# SAM9X75D1GN2 register map
Vendor: Microchip Technology; Series: SAM9X7; File version: 0
Registers are 32-bit, read-write, reset 0x0 unless marked. A register's access mark holds for its fields unless they carry their own. Offsets are from the block's base; [hi:lo] are bit positions; lines under a group give offsets from that group; {n}, {i} and the like mark numbered series; 'fields as' and 'values as' point back to an identical list.

## GMAC (part 2 of 2) — Gigabit Ethernet MAC
Base 0xF802C000
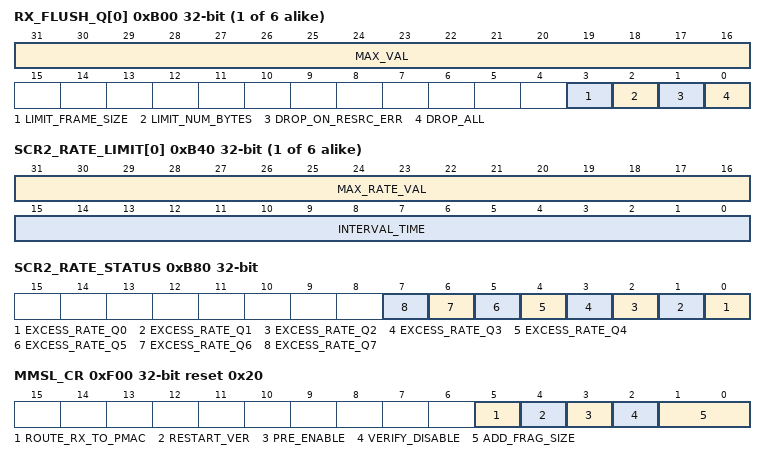
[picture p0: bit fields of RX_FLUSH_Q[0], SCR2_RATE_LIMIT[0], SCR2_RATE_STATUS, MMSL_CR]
{0xB00+4i} RX_FLUSH_Q[{i}] (i=0..5) — Receive Queue Flush Register (index = 0)
  [31:16] MAX_VAL — Maximum Value for the Received Frame Size or Number of 128-Byte Chunk
  [3] LIMIT_FRAME_SIZE — Maximum Frame-length Received
    0=DISABLED (No effect.); 1=ENABLED (When set, MAX_VAL indicates the maximum frame-length in bytes that may be received. Frames exceeding this length will be dropped. This traffic policing function is relevant to the 802.1Qci standard which specifies stream filtering based on a maximum service data unit (SDU) size.)
  [2] LIMIT_NUM_BYTES — Limitation of the Number of 128-Byte Chunk of Data Stored in the Memory of this Queue
    0=DISABLED (No effect.); 1=ENABLED (Limits the number of 128 byte chunks of data received for this queue and already stored in the memory of the queue awaiting DMA memory writes to the value defined in the field MAX_VAL.)
  [1] DROP_ON_RESRC_ERR — Drop on Resource Error
    0=DISABLED (No effect.); 1=ENABLED (If a free DMA descriptor for this queue cannot be obtained (also referred to as lack of descriptor resource and occurs when the software either cannot free up descriptors quickly enough to meet the receive traffic rate or has deliberately decided not to free any descriptors), all new frames received on this queue will be automatically discarded.)
  [0] DROP_ALL — Drop All Frames
    0=DISABLED (No effect.); 1=ENABLED (Drops all frames of this queue.)
{0xB40+4i} SCR2_RATE_LIMIT[{i}] (i=0..5) — Screening 2 Rate Limit Register (index = 0)
  [31:16] MAX_RATE_VAL — Maximum Rate Value for the Interval Time
  [15:0] INTERVAL_TIME — Interval Time for Maximum Rate Checking
0xB80 SCR2_RATE_STATUS ro — Screening 2 Rate Status Register
  [all] fields
    0=No excessive rate in screener since the last read of GMAC_SCR2_RATE_STATUS; 1=A screener rate limiting mechanism has been triggered since the last read of GMAC_SCR2_RATE_STATUS
  [n] EXCESS_RATE_Q{n} (n=0..7) — Excessive Screener Rate Queue {n}
0xF00 MMSL_CR reset 0x20 — MMSL Control Register
  [5] ROUTE_RX_TO_PMAC — Route Received Frames to Preemptive MAC
    0=Routes all received to express MAC (eMAC); 1=Routes all received frames to preemptive MAC (pMAC)
  [4] RESTART_VER — Restart the Verification Procedure (Write-only)
    0=No effect; 1=Restarts the verification procedure. Writing a one to this bit has no effect if any of the following are true: PRE_ENABLE=0, VERIFY_DISABLE=1 or the verification procedure is already in progress. When preemption is active, ROUTE_RX_TO_PMAC must be set to zero before writing to the RESTART_VER bit. This bit always returns zero when read.
  [3] PRE_ENABLE — Preemption Operation Enable
    0=Disables the preemption operation and verify mpackets will not be responded to or sent. If a preemption is in progress, the current preemption will complete and no more preemption will occur.; 1=Enables the preemption by starting the verification procedure when VERIFY_DISABLE=0. Preemption can occur only once the verification process completes. If VERIFY_DISABLE=1, preemption can occur immediately.
  [2] VERIFY_DISABLE — 802.3br Support Check for the Link Partner
    0=Enables the 802.3br support check for the link partner; 1=Disables the 802.3br support check for the link partner and preemption is enabled as soon as PRE_ENABLE=1
  [1:0] ADD_FRAG_SIZE — PMAC Minimum Number of Bytes before Preemption
    0=64_BYTES (A minimum of 64 bytes can be sent by pMAC before any preemption. The value can be changed only when PRE_ENABLE is cleared); 1=128_BYTES (A minimum of 128 bytes can be sent by pMAC before any preemption. The value can be changed only when PRE_ENABLE is cleared); 2=192_BYTES (A minimum of 192 bytes can be sent by pMAC before any preemption. The value can be changed only when PRE_ENABLE is cleared); 3=256_BYTES (A minimum of 256 bytes can be sent by pMAC before any preemption. The value can be changed only when PRE_ENABLE is cleared)
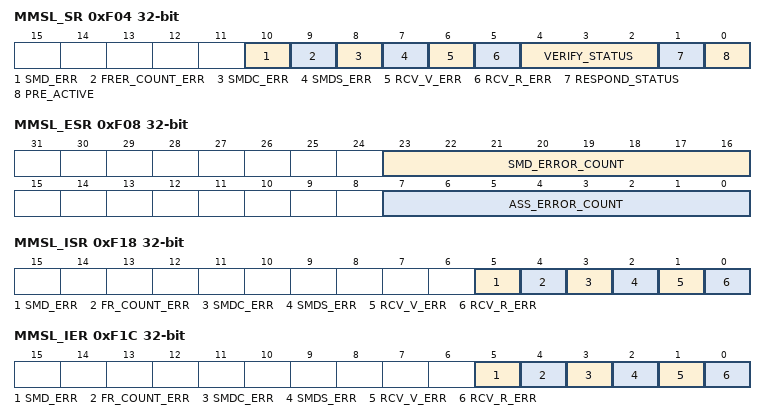
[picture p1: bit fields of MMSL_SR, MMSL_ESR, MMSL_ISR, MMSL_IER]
0xF04 MMSL_SR ro — MMSL Status Register
  [10] SMD_ERR — Illegal Start Mpacket Delimiter Received (Clear on read)
    0=No error since the last read of GMAC_MMSL_SR; 1=An illegal SMD (different from Express, Verify, Response, Start Preemptible or Continuation Preemptible SMD) has been received since the last read of GMAC_MMSL_SR
  [9] FRER_COUNT_ERR — Frame Counter Error (Clear on read)
    0=No error since the last read of GMAC_MMSL_SR; 1=A frame counter error occurred since the last read of GMAC_MMSL_SR. A frame counter error occurs when the SMD-C received indicates a different frame count than expected (i.e. the fragment belongs to another frame and not to the Start packet already received before this) or when a fragment error happened, which means the field following the SMD-C received was encoding a different fragment count than it was supposed to be.
  [8] SMDC_ERR — SMD-C Received When Waiting an SMD-S (Clear on read)
    0=No error since the last read of GMAC_MMSL_SR; 1=An SMD-C has been received when an SMD-S was expected, since the last read of GMAC_MMSL_SR
  [7] SMDS_ERR — SMD-S Received When Waiting an SMD-C (Clear on read)
    0=No error since the last read of GMAC_MMSL_SR; 1=An SMD-S has been received when an SMD-C was expected, since the last read of GMAC_MMSL_SR
  [6] RCV_V_ERR — Incorrect Verification Mpacket Received (Clear on read)
    0=No error since the last read of GMAC_MMSL_SR; 1=An incorrect verification mPacket has been received since the last read of GMAC_MMSL_SR
  [5] RCV_R_ERR — Incorrect Response Mpacket Received (Clear on read)
    0=No error since the last read of GMAC_MMSL_SR; 1=An incorrect response mPacket has been received since the last read of GMAC_MMSL_SR
  [4:2] VERIFY_STATUS — Verification Status
    0=INIT_VERIFICATION (Initialization); 1=VERIFICATION_IDLE (Idle); 2=SEND_VERIFY (Sending a verify command); 3=WAIT_FOR_RESPONSE (Waiting for a response); 4=VERIFIED; 5=VERIFY_FAIL (Failure during the verify operation)
  [1] RESPOND_STATUS — Response Status
    0=R_IDLE (Idle); 1=SEND_RESPOND (Sending)
  [0] PRE_ACTIVE — Preemption Status
    0=Preemption is inactive; 1=Preemption is active when the verification process is completed or when GMAC_MMSL_CR.VERIFY_DISABLE=1 and GMAC_MMSL_CR.PRE_ACTIVE=1
0xF08 MMSL_ESR ro — MMSL Error Statistics Register
  [23:16] SMD_ERROR_COUNT — Number of Rejected Frames or Fragments due to unknown SMD (Clear on read)
  [7:0] ASS_ERROR_COUNT — Number of Frames with Reassembly Errors (Clear on read)
0xF0C MMSL_ASS_OK ro — MMSL Frame Re-Assembled OK Register
  [16:0] ASS_OK_COUNT — Number of Correctly Re-Assembled Frames (Clear on read)
0xF10 MMSL_RXFRAG_CNT ro — MMSL Received Fragment Counter Register
  [16:0] FRAG_COUNT_RX — Number of Received Fragments (Clear on read)
0xF14 MMSL_TXFRAG_CNT ro — MMSL Transmitted Fragment Counter Register
  [16:0] FRAG_COUNT_TX — Number of Transmitted Fragments (Clear on read)
0xF18 MMSL_ISR — MMSL Interrupt Status Register
  [5] SMD_ERR — Illegal SMD Received (Clear on read)
    0=No illegal SMD received since the last read of GMAC_MMSL_ISR; 1=Illegal SMD received (different from Express, Verify, Response, Start Preemptible or Continuation Preemptible) since the last read of GMAC_MMSL_ISR
  [4] FR_COUNT_ERR — Illegal SMD Received (Clear on read)
    0=No frame count error detected since the last read of GMAC_MMSL_ISR; 1=The SMD-C received since the last read of GMAC_MMSL_ISR, indicates a different frame count than expected (i.e. the fragment belongs to another frame and not to the Start packet already received before this) or if a Fragment error happened, which means the field following the SMD-C received was encoding a different fragment count than it was supposed to be.
  [3] SMDC_ERR — SMD-C Received When Waiting an SMD-S (Clear on read)
    values as MMSL_SR.SMDC_ERR
  [2] SMDS_ERR — SMD-S Received When Waiting an SMD-C (Clear on read)
    values as MMSL_SR.SMDS_ERR
  [1] RCV_V_ERR — Incorrect Verification Mpacket Received (Clear on read)
    values as MMSL_SR.RCV_V_ERR
  [0] RCV_R_ERR — Incorrect Response Mpacket Received (Clear on read)
    values as MMSL_SR.RCV_R_ERR
0xF1C MMSL_IER — MMSL Interrupt Enable Register
  [5] SMD_ERR — Illegal SMD Received
  [4] FR_COUNT_ERR — Illegal SMD Received
  [3] SMDC_ERR — SMD-C Received When Waiting an SMD-S
  [2] SMDS_ERR — SMD-S Received When Waiting an SMD-C
  [1] RCV_V_ERR — Incorrect Verification Mpacket Received
  [0] RCV_R_ERR — Incorrect Response Mpacket Received
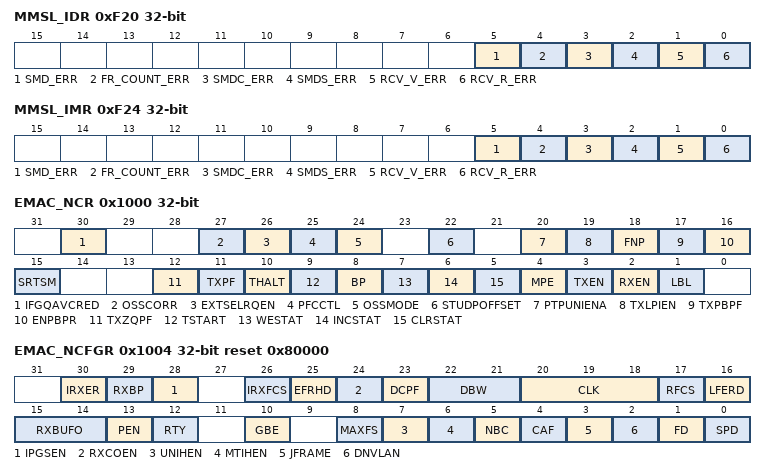
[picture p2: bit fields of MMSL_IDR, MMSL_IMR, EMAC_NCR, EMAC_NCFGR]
0xF20 MMSL_IDR — MMSL Interrupt Disable Register
  fields as MMSL_IER
0xF24 MMSL_IMR ro — MMSL Interrupt Mask Register
  fields as MMSL_IER
0x1000 EMAC_NCR — Express MAC Network Control Register
  [30] IFGQAVCRED — Credit-Based Shaping Algorithm Modification
    0=No modification of the CBS algorithm; 1=Modifies the CBS algorithm so the IFG/IPG associated with a transmit frame counts towards its 802.1Qav credit
  [27] OSSCORR — 1588 One Step Sync Mode Correction Field
    0=Disables updating the correction field of PTP 1588 version 2 sync frames by adding current TSU timer value; 1=Enables updating the correction field of PTP 1588 version 2 sync frames by adding current TSU timer value
  [26] EXTSELRQEN — External Selection of Receive Queue Enable
    0=Disables external selection of receive queue; 1=Enables external selection of receive queue
  [25] PFCCTL — Multiple PFC Pause quantum Enable
    0=Disables multiple PFC pause quantums; 1=Enables multiple PFC pause quantums, one per pause priority
  [24] OSSMODE — One Step Sync Mode
    0=1588 One Step Sync Mode is disabled; 1=1588 One Step Sync Mode is enabled. Replaces timestamp field in the 1588 header for TX Sync Frames with the current TSU timer value.
  [22] STUDPOFFSET — Store UDP Offset
    0=Normal operations; 1=The upper 16 bits of the CRC of every received frame are replaced with the offset from start of frame to the beginning of the UDP or TCP header. The lower 16 bits of the CRC are replaced with zero and reserved for future use. The offset is measured in units of 2 bytes.
  [20] PTPUNIENA — Detection of Unicast PTP Frames Enable
    0=Disables detection of unicast PTP frames; 1=Enables detection of unicast PTP frames
  [19] TXLPIEN — Enable LPI Transmission
  [18] FNP — Flush Next Packet (Write-only)
    0=No effect; 1=Flushes the next packet from the receive memory. This will only have an effect if the DMA is not currently writing a packet already stored in the receive memory to system memory.
  [17] TXPBPF — Transmit PFC Priority-based Pause Frame (Write-only)
    0=No effect; 1=Takes the values stored in the Transmit PFC Pause Register
  [16] ENPBPR — Enable PFC Priority-based Pause Reception
    0=Disables PFC Priority Based Pause Reception capabilities; 1=Enables PFC Priority Based Pause Reception capabilities by enabling the PFC negotiation and recognition of priority-based pause frames
  [15] SRTSM — Store Receive Timestamp to Memory
    0=Normal operation; 1=Causes the CRC of every received frame to be replaced with the value of the nanoseconds field of the 1588 timer that was captured as the receive frame passed the message timestamp point. Note that bit RFCS in register GMAC_NCFGR may not be set to 1 when the timer should be captured.
  [12] TXZQPF — Transmit Zero Quantum Pause Frame (Write-only)
    0=No effect; 1=Generates a pause frame with zero quantum to be transmitted
  [11] TXPF — Transmit Pause Frame (Write-only)
    0=No effect; 1=Generates a pause frame to be transmitted
  [10] THALT — Transmit Halt (Write-only)
    0=No effect; 1=Halts transmission as soon as any ongoing frame transmission ends
  [9] TSTART — Start Transmission (Write-only)
    0=No effect; 1=Starts transmission
  [8] BP — Back Pressure
    0=No effect; 1=When the MAC is set in 10M or 100M Half Duplex mode, forces collisions on all received frames. Ignored in Gigabit Half Duplex mode.
  [7] WESTAT — Write Enable for Statistics Registers
    0=Forces the statistics registers to be in read-only mode for normal operation mode; 1=Makes the statistics registers writable for functional test purposes
  [6] INCSTAT — Increment Statistics Registers (Write-only)
  [5] CLRSTAT — Clear Statistics Registers (Write-only)
    0=No effect; 1=Clears the statistics registers
  [4] MPE — Management Port Enable
    0=Forces GMDIO to high impedance state and MDC low; 1=Enables the management port
  [3] TXEN — Transmit Enable
    0=Stops transmission immediately, the transmit pipeline and control registers will be cleared and the Transmit Queue Pointer Register will reset to point to the start of the transmit descriptor list; 1=Enables the GMAC transmitter to send data
  [2] RXEN — Receive Enable
    0=Stops frame reception immediately and the receive pipeline will be cleared. The Receive Queue Pointer Register is unaffected.; 1=Enables the GMAC to receive data
  [1] LBL — Loop Back Local
    0=Normal operating mode (no loop back); 1=Connects GTX to GRX, GTXEN to GRXDV and forces Full Duplex mode. GRXCK and GTXCK may malfunction as the GMAC is switched into and out of internal loop back. It is important that receive and transmit circuits have already been disabled when making the switch into and out of internal loop back.
0x1004 EMAC_NCFGR reset 0x80000 — Express MAC Network Configuration Register
  [30] IRXER — Ignore Receive Error from PHY
    0=IRXER_0; 1=GRXER has no effect on the GMAC's operation when GRXDV is low. Set this bit when using the RGMII wrapper in Half Duplex mode.
  [29] RXBP — Receive Bad Preamble
    0=Rejects frames with non-standard preamble; 1=Accepts frames with non-standard preamble
  [28] IPGSEN — Inter Packet Gap Stretch Enable
    0=The transmit IPG cannot be increased; 1=The transmit IPG can be increased above 96 bit times depending on the previous frame length using the IPG Stretch Register
  [26] IRXFCS — Ignore RX FCS
    0=Normal operation, frames with FCS/CRC errors are rejected; 1=Frames with FCS/CRC errors are rejected. FCS error statistics are still collected for frames with bad FCS and FCS status is recorded in frame's DMA descriptor.
  [25] EFRHD — Enable Frames Received in Half Duplex
    0=Disables frames to be received in Half Duplex mode while transmitting; 1=Enables frames to be received in Half Duplex mode while transmitting
  [24] RXCOEN — Receive Checksum Offload Enable
    0=Disables the receive checksum engine. Frames with bad IP, TCP or UDP checksums are accepted.; 1=Enables the receive checksum engine. Frames with bad IP, TCP or UDP checksums are discarded.
  [23] DCPF — Disable Copy of Pause Frames
    0=Copies pause frames to the system memory; 1=Prevents valid pause frames being copied to memory. Pause frames are not copied to memory regardless of the state of the Copy All Frames bit, whether a hash match is found or whether a type ID match is identified. If a destination address match is found, the pause frame will be copied to memory. Note that valid pause frames received will still increment pause statistics and pause the transmission of frames as required.
  [22:21] DBW — Always Written to 0
  [20:18] CLK — MDC Clock Division
    0=MCK_8 (MCK divided by 8 (MCK up to 20 MHz)); 1=MCK_16 (MCK divided by 16 (MCK up to 40 MHz)); 2=MCK_32 (MCK divided by 32 (MCK up to 80 MHz)); 3=MCK_48 (MCK divided by 48 (MCK up to 120 MHz)); 4=MCK_64 (MCK divided by 64 (MCK up to 160 MHz)); 5=MCK_96 (MCK divided by 96 (MCK up to 240 MHz))
  [17] RFCS — Remove FCS
    0=Includes the received frame check sequence (last 4 bytes) when writing to memory; 1=Excludes the received frame check sequence (last 4 bytes) when writing to memory. The frame length indicated will be reduced by four bytes in this mode.
  [16] LFERD — Length Field Error Frame Discard
    0=Accepts frames with a measured length shorter than the extracted length field; 1=Discards frames with a measured length shorter than the extracted length field (as indicated by bytes 13 and 14 in a non-VLAN tagged frame). This only applies to frames with a length field less than 0x0600.
  [15:14] RXBUFO — Receive Buffer Offset
  [13] PEN — Pause Enable
    0=Does not pause the transmission when a non-zero 802.3 classic pause frame is received; 1=Pauses transmission when a non-zero 802.3 classic pause frame is received and PFC has not been negotiated
  [12] RTY — Retry Test0
    0=Normal operation; 1=The backoff between collisions will always be one slot time and helps test the too many retries condition. Also used in the pause frame tests to reduce the pause counter's decrement time from 512 bit times, to every GRXCK cycle.
  [10] GBE — Gigabit Mode Enable
    0=Operates in 10/100Mbps mode; 1=Operates in Gigabit mode
  [8] MAXFS — 1536 Maximum Frame Size
    0=Rejects frame sizes above 1518 bytes; 1=Accepts frames up to 1536 bytes in length. Normally the GMAC would reject any frame above 1518 bytes.
  [7] UNIHEN — Unicast Hash Enable
    0=Rejects unicast frames; 1=Accepts unicast frames when the 6-bit hash function of the destination address points to a bit that is set in the Hash Register
  [6] MTIHEN — Multicast Hash Enable
    0=Rejects multicast frames; 1=Accepts multicast frames when the 6-bit hash function of the destination address points to a bit that is set in the Hash Register
  [5] NBC — No Broadcast
    0=Accepts broadcast frames; 1=Rejects frames addressed to the broadcast address of all ones
  [4] CAF — Copy All Frames
    0=Discards invalid frames; 1=Accepts all valid frames
  [3] JFRAME — Jumbo Frame Size
    0=Disables jumbo frames; 1=Enables jumbo frames up to 10240 bytes to be accepted. The default length is 10240 bytes.
  [2] DNVLAN — Discard Non-VLAN FRAMES
    0=Passes all frames to address matching logic; 1=Passes only VLAN tagged frames to the address matching logic
  [1] FD — Full Duplex
    0=Half-duplex mode; 1=The transmit block ignores the state of collision and carrier sense and allows receive while transmitting
  [0] SPD — Speed
    0=MAC operates at 10 Mbps; 1=MAC Operates at 100 Mbps
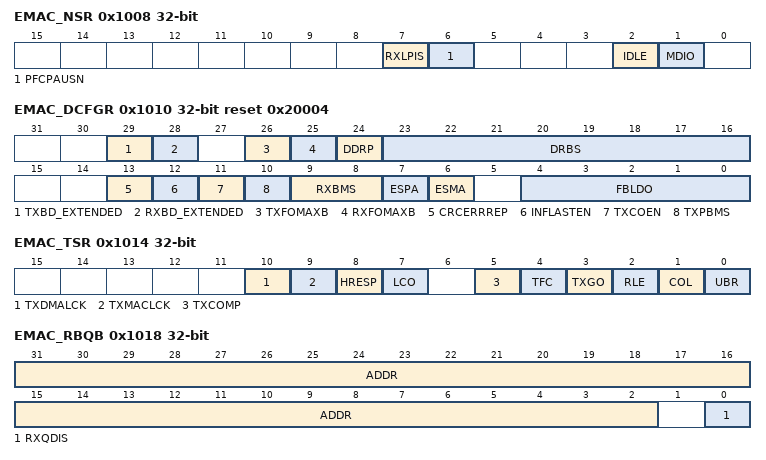
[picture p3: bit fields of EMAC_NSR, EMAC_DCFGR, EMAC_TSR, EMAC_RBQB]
0x1008 EMAC_NSR ro — Express MAC Network Status Register
  [7] RXLPIS — LPI Indication
  [6] PFCPAUSN — PFC Pause Negotiated
  [2] IDLE — PHY Management Logic Idle
  [1] MDIO — MDIO Input Status
0x1010 EMAC_DCFGR reset 0x20004 — Express MAC DMA Configuration Register
  [29] TXBD_EXTENDED — Transmit Buffer Descriptor Extended Mode
    0=Disables Transmit Buffer Data Extended mode; 1=Enables Transmit Buffer Data Extended mode
  [28] RXBD_EXTENDED — Receive Buffer Descriptor Extended Mode
    0=Disables Receive Buffer Data Extended mode; 1=Enables Receive Buffer Data Extended mode
  [26] TXFOMAXB — Force Transmit Max Burst Length
  [25] RXFOMAXB — Force Receive Max Burst Length
  [24] DDRP — DMA Discard Receive Packets
  [23:16] DRBS — DMA Receive Buffer Size
    2=128 bytes; 24=1536 bytes (1 x max length frame/buffer); 160=10240 bytes (1 x 10K jumbo frame/buffer)
  [13] CRCERRREP — CRC Errors Report
    0=Bit 16 of the receive buffer descriptor represents the Canonical format indicator (CFI) bit as extracted from the receive frame (if the receive buffer descriptor is pointing to the last data buffer of the receive frame and the received frame was VLAN tagged); 1=Bit 16 of the receive buffer descriptor represents the FCS/CRC error (only if frames with FCS are copied to memory as enabled by bit 26 in the Network Configuration register)
  [12] INFLASTEN — Infinite Size for Last Buffer Enable
  [11] TXCOEN — Transmitter Checksum Generation Offload Enable
  [10] TXPBMS — Transmitter Packet Buffer Memory Size Select
    0=TWO_KB (Do not use top address bit (2 Kbytes).); 1=FOUR_KB (Use full configured addressable space (4 Kbytes).)
  [9:8] RXBMS — Receiver Packet Buffer Memory Size Select
    0=EIGHTH (4/8 Kbyte Memory Size); 1=QUARTER (4/4 Kbytes Memory Size); 2=HALF (4/2 Kbytes Memory Size); 3=FULL (4 Kbytes Memory Size)
  [7] ESPA — Endian Swap Mode Enable for Packet Data Accesses
    0=LITTLE_ENDIAN (Selects Little-endian endianism for system bus transfers.); 1=BIG_ENDIAN (Selects swapped endianism for system bus transfers.)
  [6] ESMA — Endian Swap Mode Enable for Management Descriptor Accesses
    values as ESPA
  [4:0] FBLDO — Fixed Burst Length for DMA Data Operations:
    1=SINGLE (Always use single access on system bus); 4=INCR4 (Attempt to use 4-beat bursts on system bus (Default)); 8=INCR8 (Attempt to use 8-beat bursts on system bus bursts); 16=INCR16 (Attempt to use 16-beat bursts on system bus bursts)
0x1014 EMAC_TSR — Express MAC Transmit Status Register
  [10] TXDMALCK — Transmit DMA Lockup (Clear by Writing a 1)
  [9] TXMACLCK — Transmit MAC Lockup (Clear by Writing a 1)
  [8] HRESP — System Bus Response (Clear by Writing a 1)
  [7] LCO — Late Collision Occurred (Clear by Writing a 1)
  [5] TXCOMP — Transmit Complete (Clear by Writing a 1)
  [4] TFC — Transmit Frame Corruption Due to System Bus Error (Clear by Writing a 1)
  [3] TXGO — Transmit Go (Read only)
  [2] RLE — Retry Limit Exceeded (Clear by Writing a 1)
  [1] COL — Collision Occurred (Clear by Writing a 1)
  [0] UBR — Used Bit Read (Clear by Writing a 1)
0x1018 EMAC_RBQB — Express MAC Receive Buffer Queue Base Address Register
  [31:2] ADDR — Receive Buffer Queue Base Address
  [0] RXQDIS — Receive Queue Disable
    0=Queue is enabled; 1=Queue is disabled. Used to reduce the number of active queues and should only be changed while receive is not enabled.
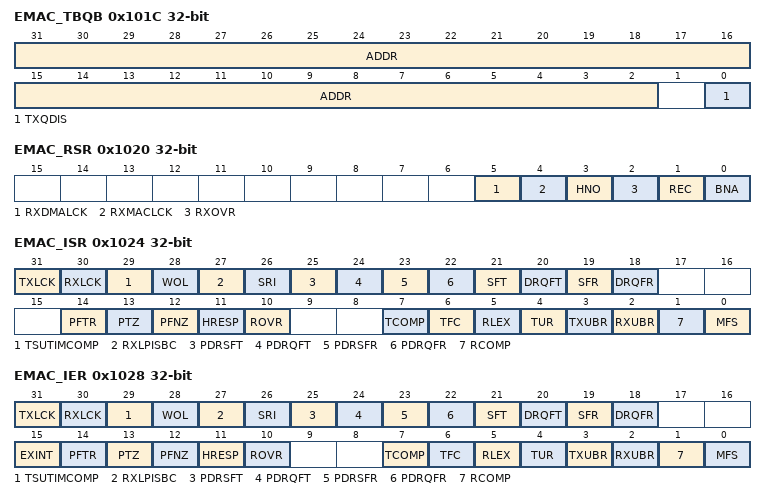
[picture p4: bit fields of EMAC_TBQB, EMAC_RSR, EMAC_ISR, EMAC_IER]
0x101C EMAC_TBQB — Express MAC Transmit Buffer Queue Base Address Register
  [31:2] ADDR — Transmit Buffer Queue Base Address
  [0] TXQDIS — Transmit Queue Disable
    0=Queue is enabled; 1=Queue is disabled. Used to reduce the number of active queues and should only be changed while transmit is not enabled.
0x1020 EMAC_RSR — Express MAC Receive Status Register
  [5] RXDMALCK — Receive DMA Lockup (Clear by Writing a 1)
  [4] RXMACLCK — Receive MAC Lockup (Clear by Writing a 1)
  [3] HNO — System Bus Error (Clear by Writing a 1)
  [2] RXOVR — Receive Overrun (Clear by Writing a 1)
  [1] REC — Frame Received (Clear by Writing a 1)
  [0] BNA — Buffer Not Available (Clear by Writing a 1)
0x1024 EMAC_ISR ro — Express MAC Interrupt Status Register
  [31] TXLCK — Transmit Path Locked (Cleared on read)
  [30] RXLCK — Receive Path Locked (Cleared on read)
  [29] TSUTIMCOMP — TSU Timer Comparison (Cleared on read)
  [28] WOL — Wake On LAN (Cleared on read)
  [27] RXLPISBC — Receive LPI indication Status Bit Change (Cleared on read)
  [26] SRI — TSU Seconds Register Increment (Cleared on read)
  [25] PDRSFT — PDelay Response Frame Transmitted (Cleared on read)
  [24] PDRQFT — PDelay Request Frame Transmitted (Cleared on read)
  [23] PDRSFR — PDelay Response Frame Received (Cleared on read)
  [22] PDRQFR — PDelay Request Frame Received (Cleared on read)
  [21] SFT — PTP Sync Frame Transmitted (Cleared on read)
  [20] DRQFT — PTP Delay Request Frame Transmitted (Cleared on read)
  [19] SFR — PTP Sync Frame Received (Cleared on read)
  [18] DRQFR — PTP Delay Request Frame Received (Cleared on read)
  [14] PFTR — Pause Frame Transmitted (Cleared on read)
  [13] PTZ — Pause Time Zero (Cleared on read)
  [12] PFNZ — Pause Frame with Non-zero Pause Quantum Received (Cleared on read)
  [11] HRESP — System Bus Error (Cleared on read)
  [10] ROVR — Receive Overrun (Cleared on read)
  [7] TCOMP — Transmit Complete (Cleared on read)
  [6] TFC — Transmit Frame Corruption Due to System Bus Error (Cleared on read)
  [5] RLEX — Retry Limit Exceeded or Late Collision (Cleared on read)
  [4] TUR — Transmit Underrun (Cleared on read)
  [3] TXUBR — TX Used Bit Read (Cleared on read)
  [2] RXUBR — RX Used Bit Read (Cleared on read)
  [1] RCOMP — Receive Complete (Cleared on read)
  [0] MFS — Management Frame Sent (Cleared on read)
0x1028 EMAC_IER wo — Express MAC Interrupt Enable Register
  [31] TXLCK — Transmit Path Lockup Detected
  [30] RXLCK — Receive Path Lockup Detected
  [29] TSUTIMCOMP — TSU Timer Comparison
  [28] WOL — Wake On LAN
  [27] RXLPISBC — Enable RX LPI Indication
  [26] SRI — TSU Seconds Register Increment
  [25] PDRSFT — PDelay Response Frame Transmitted
  [24] PDRQFT — PDelay Request Frame Transmitted
  [23] PDRSFR — PDelay Response Frame Received
  [22] PDRQFR — PDelay Request Frame Received
  [21] SFT — PTP Sync Frame Transmitted
  [20] DRQFT — PTP Delay Request Frame Transmitted
  [19] SFR — PTP Sync Frame Received
  [18] DRQFR — PTP Delay Request Frame Received
  [15] EXINT — External Interrupt
  [14] PFTR — Pause Frame Transmitted
  [13] PTZ — Pause Time Zero
  [12] PFNZ — Pause Frame with Non-zero Pause Quantum Received
  [11] HRESP — System Bus Error
  [10] ROVR — Receive Overrun
  [7] TCOMP — Transmit Complete
  [6] TFC — Transmit Frame Corruption Due to System Bus Error
  [5] RLEX — Retry Limit Exceeded or Late Collision
  [4] TUR — Transmit Underrun
  [3] TXUBR — TX Used Bit Read
  [2] RXUBR — RX Used Bit Read
  [1] RCOMP — Receive Complete
  [0] MFS — Management Frame Sent
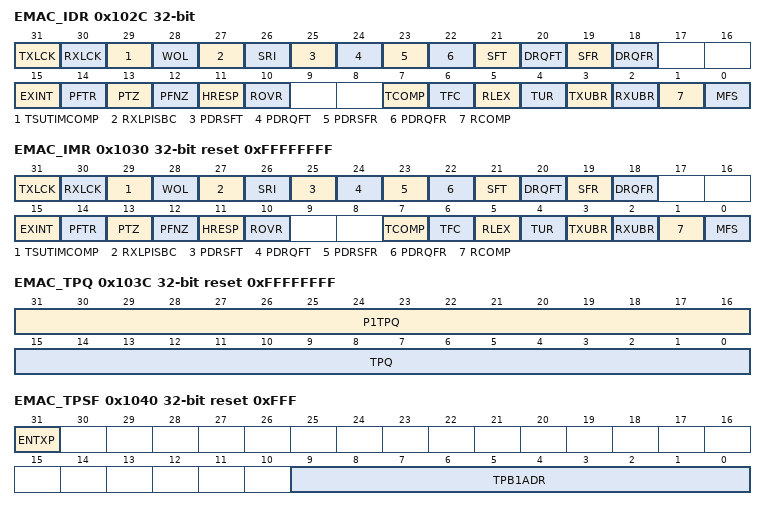
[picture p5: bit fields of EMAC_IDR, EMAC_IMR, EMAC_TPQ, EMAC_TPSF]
0x102C EMAC_IDR wo — Express MAC Interrupt Disable Register
  fields as EMAC_IER
0x1030 EMAC_IMR reset 0xFFFFFFFF — Express MAC Interrupt Mask Register
  fields as EMAC_IER
0x1038 EMAC_RPQ ro — Express MAC Receive Pause Quantum Register
  [15:0] RPQ — Received Pause Quantum
0x103C EMAC_TPQ reset 0xFFFFFFFF — Express MAC Transmit Pause Quantum Register
  [31:16] P1TPQ — Priority 1 Transmit Pause Quantum
  [15:0] TPQ — Transmit Pause Quantum
0x1040 EMAC_TPSF reset 0xFFF — Express MAC TX Partial Store and Forward Register
  [31] ENTXP — Enable TX Partial Store and Forward Operation
  [9:0] TPB1ADR — Transmit Partial Store and Forward Address
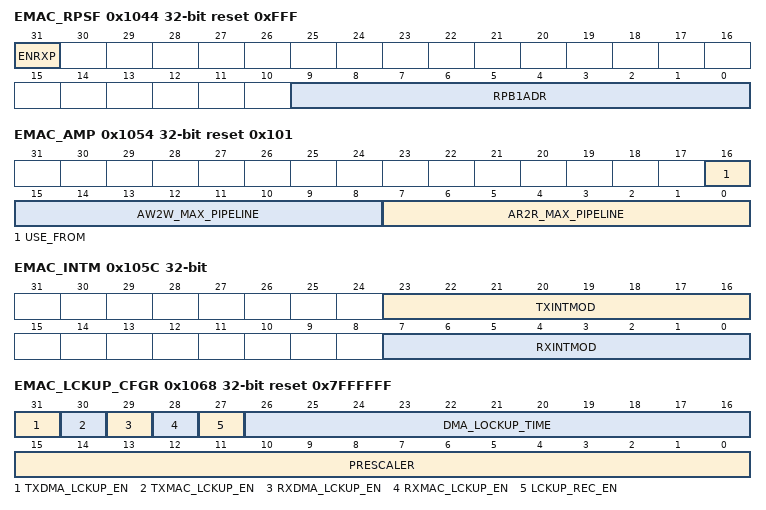
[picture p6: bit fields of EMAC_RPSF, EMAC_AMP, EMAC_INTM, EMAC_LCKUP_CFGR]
0x1044 EMAC_RPSF reset 0xFFF — Express MAC RX Partial Store and Forward Register
  [31] ENRXP — Enable RX Partial Store and Forward Operation
  [9:0] RPB1ADR — Receive Partial Store and Forward Address
0x1048 EMAC_RJFML reset 0x2800 — Express MAC RX Jumbo Frame Max Length Register
  [13:0] FML — Frame Max Length
0x1054 EMAC_AMP reset 0x101 — Express MAC System Bus Maximum Pipeline
  [16] USE_FROM — Address Write Bus to Write Data Bus Maximum Pipeline
    0=AW2W (Operates the AW2W_MAX_PIPELINE field between AW to W channel.); 1=AW2B (Operates the AW2W_MAX_PIPELINE field between AW to B channel.)
  [15:8] AW2W_MAX_PIPELINE — Address Write Bus to Write Data Bus Maximum Pipeline
  [7:0] AR2R_MAX_PIPELINE — Address Read Bus to Read Data Bus Maximum Pipeline
0x105C EMAC_INTM — Express MAC Interrupt Moderation Register
  [23:16] TXINTMOD — Transmit Interrupt Moderation
  [7:0] RXINTMOD — Receive Interrupt Moderation
0x1060 EMAC_SYSWT — Express MAC System Wake-Up Time Register
  [15:0] SYSWKUPTIME — System Wake-up Time
0x1068 EMAC_LCKUP_CFGR reset 0x7FFFFFF — Express MAC Lockup Detection and Recovery Configuration
  [31] TXDMA_LCKUP_EN — Transmit DMA Lockup Detector Enable
    0=Disables the monitor that detects lockups in the transmit DMA; 1=Enables the monitor that detects lockups in the transmit DMA
  [30] TXMAC_LCKUP_EN — Transmit MAC Lockup Detector Enable
    0=Disables the monitor that detects lockups in the transmit MAC; 1=Enables the monitor that detects lockups in the transmit MAC
  [29] RXDMA_LCKUP_EN — Receive DMA Lockup Detector Enable
    0=Disables the monitor that detects lockups in the receive DMA; 1=Enables the monitor that detects lockups in the receive DMA
  [28] RXMAC_LCKUP_EN — Receive MAC Lockup Detector Enable
    0=Disables the monitor that detects lockups in the receive MAC; 1=Enables the monitor that detects lockups in the receive MAC
  [27] LCKUP_REC_EN — Lockup RecoveryEnable
    0=No effect; 1=Forces the EMAC in Reset mode when a lockup.is detected on the transmit or receive data paths
  [26:16] DMA_LOCKUP_TIME — Timeout Value for Receive and Transmit DMA
  [15:0] PRESCALER — Prescaler Value for Timeout
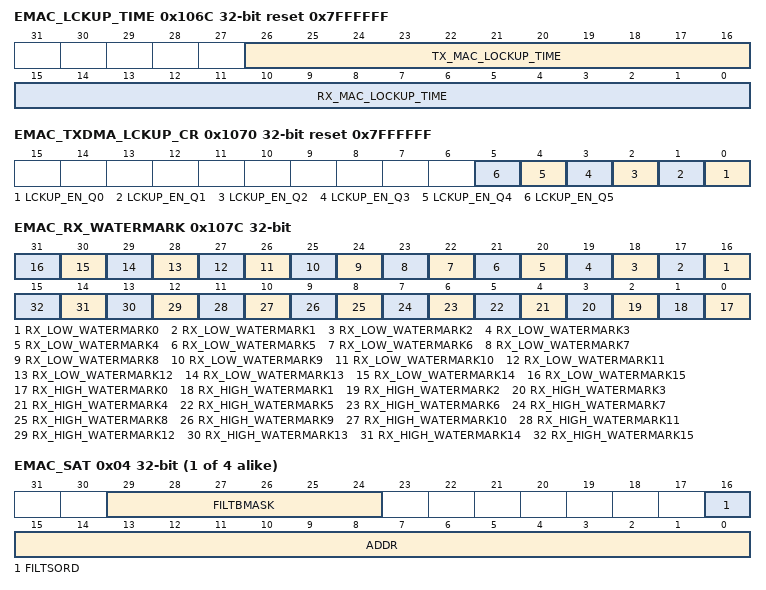
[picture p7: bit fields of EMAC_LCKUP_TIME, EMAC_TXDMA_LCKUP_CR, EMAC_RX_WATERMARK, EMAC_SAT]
0x106C EMAC_LCKUP_TIME reset 0x7FFFFFF — Express MAC Lockup Detection Time
  [26:16] TX_MAC_LOCKUP_TIME — Transmit MAC Lockup Detector Time
  [15:0] RX_MAC_LOCKUP_TIME — Receive MAC Lockup Detector Time
0x1070 EMAC_TXDMA_LCKUP_CR reset 0x7FFFFFF — Express MAC Transmit DMA Lockup Control Register
  [all] fields
    0=Disables the transmit DMA lockup timer for queue x. The number of outstanding packets are still counted but the actual timer does not run.; 1=Enables the transmit DMA lockup timer for queue x
  [n] LCKUP_EN_Q{n} (n=0..5) — Transmit DMA Lockup Detector Enable for Queue {n}
0x107C EMAC_RX_WATERMARK — Express MAC Receive Watermark Register
  [n+16] RX_LOW_WATERMARK{n} (n=0..15) — Transmit DMA Lockup Detector Enable for Queue {n}
  [n] RX_HIGH_WATERMARK{n} (n=0..15) — Transmit DMA Lockup Detector Enable for Queue {n}
0x1080 EMAC_HRB — Express MAC Hash Register Bottom
  [31:0] ADDR — Hash Address
0x1084 EMAC_HRT — Express MAC Hash Register Top
  [31:0] ADDR — Hash Address
{0x1088+8i} GMAC_EMAC_SA[{i}] (i=0..3) group
  0x00 EMAC_SAB — Express MAC Specific Address Bottom Register
    [31:0] ADDR — Specific Address
  0x04 EMAC_SAT — Express MAC Specific Address Top Register
    [29:24] FILTBMASK — Filter Bytes Mask
      1=BIT1 (Controls whether the first byte has been received.); 2=BIT2 (Controls whether the second byte has been received.); 4=BIT3 (Controls whether the third byte has been received.); 8=BIT4 (Controls whether the fourth byte has been received.); 16=BIT5 (Controls whether the fifth byte has been received.); 32=BIT6 (Controls whether the sixth byte has been received)
    [16] FILTSORD — Filter Source or Destination MAC Address
      0=The filter is a destination address filter; 1=The filter is a source address filter
    [15:0] ADDR — Specific Address
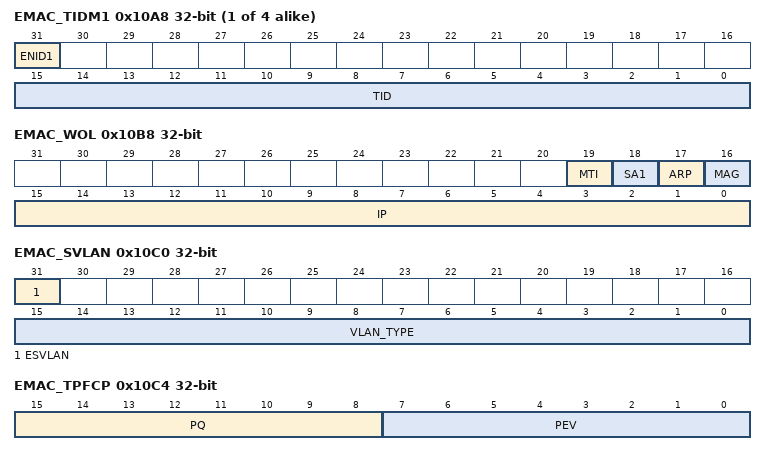
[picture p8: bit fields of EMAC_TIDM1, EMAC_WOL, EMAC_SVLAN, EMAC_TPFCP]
{0x10A4+4i} EMAC_TIDM{i} (i=1..4) — Express MAC Type ID Match {i} Register
  [31] ENID{i} — Enable Copying of TID Matched Frames
    0=TID is not part of the comparison match; 1=TID is processed for the comparison match
  [15:0] TID — Type ID Match {i}
0x10B8 EMAC_WOL — Express MAC Wake on LAN Register
  [19] MTI — Multicast Hash Event Enable
  [18] SA1 — Specific Address Register 1 Event Enable
  [17] ARP — ARP Request Event Enable
  [16] MAG — Magic Packet Event Enable
  [15:0] IP — ARP Request IP Address
0x10BC EMAC_IPGS — Express MAC IPG Stretch Register
  [15:0] FL — Frame Length
0x10C0 EMAC_SVLAN — Express MAC Stacked VLAN Register
  [31] ESVLAN — Enable Stacked VLAN Processing Mode
    0=Disable the stacked VLAN Processing mode; 1=Enable the stacked VLAN Processing mode
  [15:0] VLAN_TYPE — User Defined VLAN_TYPE Field
0x10C4 EMAC_TPFCP — Express MAC Transmit PFC Pause Register
  [15:8] PQ — Pause Quantum
  [7:0] PEV — Priority Enable Vector
0x10C8 EMAC_SAMB1 — Express MAC Specific Address 1 Mask Bottom Register
  [31:0] ADDR — Specific Address 1 Mask
0x10CC EMAC_SAMT1 — Express MAC Specific Address 1 Mask Top Register
  [15:0] ADDR — Specific Address 1 Mask
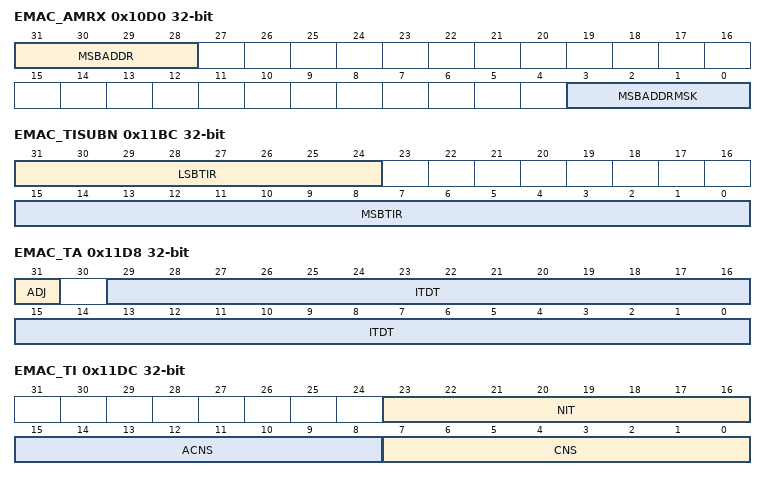
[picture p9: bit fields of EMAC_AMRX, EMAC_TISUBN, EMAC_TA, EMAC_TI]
0x10D0 EMAC_AMRX — System Memory Address Mask for RX Data Buffer Accesses Register
  [31:28] MSBADDR — MSB of the Receive Data Buffer Address
  [3:0] MSBADDRMSK — Mask of the Receive Data Buffer Address
0x10D4 EMAC_RXUDAR — Express MAC PTP RX Unicast IP Destination Address Register
  [31:0] RXUDA — Receive Unicast Destination Address
0x10D8 EMAC_TXUDAR — Express MAC PTP TX Unicast IP Destination Address Register
  [31:0] TXUDA — Transmit Unicast Destination Address
0x10DC EMAC_NSC — Express MAC 1588 Timer Nanosecond Comparison Register
  [21:0] NANOSEC — 1588 Timer Nanosecond Comparison Value
0x10E0 EMAC_SCL — Express MAC 1588 Timer Second Comparison Low Register
  [31:0] SEC — 1588 Timer Second Comparison Value
0x10E4 EMAC_SCH — Express MAC 1588 Timer Second Comparison High Register
  [15:0] SEC — 1588 Timer Second Comparison Value
0x10E8 EMAC_EFTSH ro — Express MAC PTP Event Frame Transmitted Seconds High Register
  [15:0] RUD — Register Update
0x10EC EMAC_EFRSH ro — Express MAC PTP Event Frame Received Seconds High Register
  [15:0] RUD — Register Update
0x10F0 EMAC_PEFTSH ro — Express MAC PTP Peer Event Frame Transmitted Seconds High Register
  [15:0] RUD — Register Update
0x10F4 EMAC_PEFRSH ro — Express MAC PTP Peer Event Frame Received Seconds High Register
  [15:0] RUD — Register Update
0x1100 EMAC_OTLO ro — Express MAC Octets Transmitted Low Register
  [31:0] TXO — Transmitted Octets
0x1104 EMAC_OTHI ro — Express MAC Octets Transmitted High Register
  [15:0] TXO — Transmitted Octets
0x1108 EMAC_FT ro — Express MAC Frames Transmitted Register
  [31:0] FTX — Frames Transmitted without Error
0x110C EMAC_BCFT ro — Express MAC Broadcast Frames Transmitted Register
  [31:0] BFTX — Broadcast Frames Transmitted without Error
0x1110 EMAC_MFT ro — Express MAC Multicast Frames Transmitted Register
  [31:0] MFTX — Multicast Frames Transmitted without Error
0x1114 EMAC_PFT ro — Express MAC Pause Frames Transmitted Register
  [15:0] PFTX — Pause Frames Transmitted Register
0x1118 EMAC_BFT64 ro — Express MAC 64 Byte Frames Transmitted Register
  [31:0] NFTX — 64 Byte Frames Transmitted without Error
0x111C EMAC_TBFT127 ro — Express MAC 65 to 127 Byte Frames Transmitted Register
  [31:0] NFTX — 65 to 127 Byte Frames Transmitted without Error
0x1120 EMAC_TBFT255 ro — Express MAC 128 to 255 Byte Frames Transmitted Register
  [31:0] NFTX — 128 to 255 Byte Frames Transmitted without Error
0x1124 EMAC_TBFT511 ro — Express MAC 256 to 511 Byte Frames Transmitted Register
  [31:0] NFTX — 256 to 511 Byte Frames Transmitted without Error
0x1128 EMAC_TBFT1023 ro — Express MAC 512 to 1023 Byte Frames Transmitted Register
  [31:0] NFTX — 512 to 1023 Byte Frames Transmitted without Error
0x112C EMAC_TBFT1518 ro — Express MAC 1024 to 1518 Byte Frames Transmitted Register
  [31:0] NFTX — 1024 to 1518 Byte Frames Transmitted without Error
0x1130 EMAC_GTBFT1518 ro — Express MAC Greater Than 1518 Byte Frames Transmitted Register
  [31:0] NFTX — Greater than 1518 Byte Frames Transmitted without Error
0x1134 EMAC_TUR ro — Express MAC Transmit Underruns Register
  [9:0] TXUNR — Transmit Underruns
0x1138 EMAC_SCF ro — Express MAC Single Collision Frames Register
  [17:0] SCOL — Single Collision
0x113C EMAC_MCF ro — Express MAC Multiple Collision Frames Register
  [17:0] MCOL — Multiple Collision
0x1140 EMAC_EC ro — Express MAC Excessive Collisions Register
  [9:0] XCOL — Excessive Collisions
0x1144 EMAC_LC ro — Express MAC Late Collisions Register
  [9:0] LCOL — Late Collisions
0x1148 EMAC_DTF ro — Express MAC Deferred Transmission Frames Register
  [17:0] DEFT — Deferred Transmission
0x114C EMAC_CSE ro — Express MAC Carrier Sense Errors Register
  [9:0] CSR — Carrier Sense Error
0x1150 EMAC_ORLO ro — Express MAC Octets Received Low Received Register
  [31:0] RXO — Received Octets
0x1154 EMAC_ORHI ro — Express MAC Octets Received High Received Register
  [15:0] RXO — Received Octets
0x1158 EMAC_FR ro — Express MAC Frames Received Register
  [31:0] FRX — Frames Received without Error
0x115C EMAC_BCFR ro — Express MAC Broadcast Frames Received Register
  [31:0] BFRX — Broadcast Frames Received without Error
0x1160 EMAC_MFR ro — Express MAC Multicast Frames Received Register
  [31:0] MFRX — Multicast Frames Received without Error
0x1164 EMAC_PFR ro — Express MAC Pause Frames Received Register
  [15:0] PFRX — Pause Frames Received Register
0x1168 EMAC_BFR64 ro — Express MAC 64 Byte Frames Received Register
  [31:0] NFRX — 64 Byte Frames Received without Error
0x116C EMAC_TBFR127 ro — Express MAC 65 to 127 Byte Frames Received Register
  [31:0] NFRX — 65 to 127 Byte Frames Received without Error
0x1170 EMAC_TBFR255 ro — Express MAC 128 to 255 Byte Frames Received Register
  [31:0] NFRX — 128 to 255 Byte Frames Received without Error
0x1174 EMAC_TBFR511 ro — Express MAC 256 to 511 Byte Frames Received Register
  [31:0] NFRX — 256 to 511 Byte Frames Received without Error
0x1178 EMAC_TBFR1023 ro — Express MAC 512 to 1023 Byte Frames Received Register
  [31:0] NFRX — 512 to 1023 Byte Frames Received without Error
0x117C EMAC_TBFR1518 ro — Express MAC 1024 to 1518 Byte Frames Received Register
  [31:0] NFRX — 1024 to 1518 Byte Frames Received without Error
0x1180 EMAC_TMXBFR ro — Express MAC 1519 to Maximum Byte Frames Received Register
  [31:0] NFRX — 1519 to Maximum Byte Frames Received without Error
0x1184 EMAC_UFR ro — Express MAC Undersize Frames Received Register
  [9:0] UFRX — Undersize Frames Received
0x1188 EMAC_OFR ro — Express MAC Oversize Frames Received Register
  [9:0] OFRX — Oversized Frames Received
0x118C EMAC_JR ro — Express MAC Jabbers Received Register
  [9:0] JRX — Jabbers Received
0x1190 EMAC_FCSE ro — Express MAC Frame Check Sequence Errors Register
  [9:0] FCKR — Frame Check Sequence Errors
0x1194 EMAC_LFFE ro — Express MAC Length Field Frame Errors Register
  [9:0] LFER — Length Field Frame Errors
0x1198 EMAC_RSE ro — Express MAC Receive Symbol Errors Register
  [9:0] RXSE — Receive Symbol Errors
0x119C EMAC_AE ro — Express MAC Alignment Errors Register
  [9:0] AER — Alignment Errors
0x11A0 EMAC_RRE ro — Express MAC Receive Resource Errors Register
  [17:0] RXRER — Receive Resource Errors
0x11A4 EMAC_ROE ro — Express MAC Receive Overrun Register
  [9:0] RXOVR — Receive Overruns
0x11A8 EMAC_IHCE ro — Express MAC IP Header Checksum Errors Register
  [7:0] HCKER — IP Header Checksum Errors
0x11AC EMAC_TCE ro — Express MAC TCP Checksum Errors Register
  [7:0] TCKER — TCP Checksum Errors
0x11B0 EMAC_UCE ro — Express MAC UDP Checksum Errors Register
  [7:0] UCKER — UDP Checksum Errors
0x11B4 EMAC_FLRXPCR ro — Express MAC Flushed Received Packets Counter Register
  [15:0] COUNT — Flushed Received Packets Count (cleared on read)
0x11BC EMAC_TISUBN — Express MAC 1588 Timer Increment Sub-nanoseconds Register
  [31:24] LSBTIR — Lower Significant Bits of Timer Increment Register
  [15:0] MSBTIR — Most Significant Bits of Timer Increment Register
0x11C0 EMAC_TSH — Express MAC1588 Timer Seconds High Register
  [15:0] TCS — Timer Count in Seconds
0x11D0 EMAC_TSL — Express MAC1588 Timer Seconds Low Register
  [31:0] TCS — Timer Count in Seconds
0x11D4 EMAC_TN — Express MAC1588 Timer Nanoseconds Register
  [29:0] TNS — Timer Count in Nanoseconds
0x11D8 EMAC_TA wo — Express MAC1588 Timer Adjust Register
  [31] ADJ — Adjust 1588 Timer
  [29:0] ITDT — Increment/Decrement
0x11DC EMAC_TI — Express MAC1588 Timer Increment Register
  [23:16] NIT — Number of Increments
  [15:8] ACNS — Alternative Count Nanoseconds
  [7:0] CNS — Count Nanoseconds
0x11E0 EMAC_EFTSL ro — Express MAC PTP Event Frame Transmitted Seconds Low Register
  [31:0] RUD — Register Update
0x11E4 EMAC_EFTN ro — Express MAC PTP Event Frame Transmitted Nanoseconds Register
  [29:0] RUD — Register Update
0x11E8 EMAC_EFRSL ro — Express MAC PTP Event Frame Received Seconds Low Register
  [31:0] RUD — Register Update
0x11EC EMAC_EFRN ro — Express MAC PTP Event Frame Received Nanoseconds Register
  [29:0] RUD — Register Update
0x11F0 EMAC_PEFTSL ro — Express MAC PTP Peer Event Frame Transmitted Seconds Low Register
  [31:0] RUD — Register Update
0x11F4 EMAC_PEFTN ro — Express MAC PTP Peer Event Frame Transmitted Nanoseconds Register
  [29:0] RUD — Register Update
0x11F8 EMAC_PEFRSL ro — Express MAC PTP Peer Event Frame Received Seconds Low Register
  [31:0] RUD — Register Update
0x11FC EMAC_PEFRN ro — Express MAC PTP Peer Event Frame Received Nanoseconds Register
  [29:0] RUD — Register Update
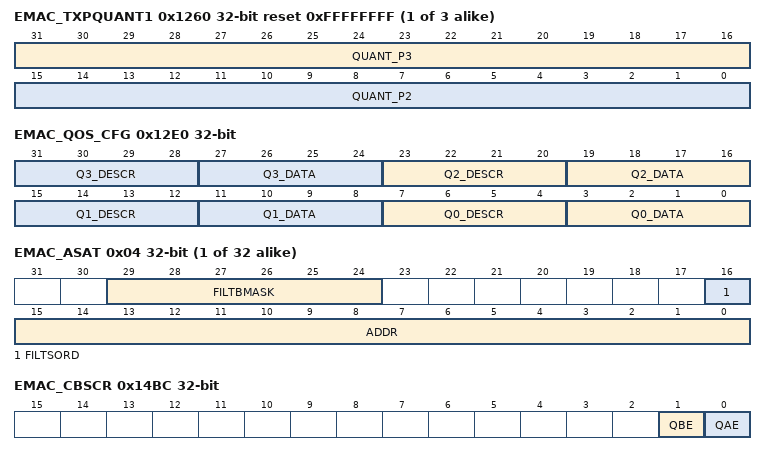
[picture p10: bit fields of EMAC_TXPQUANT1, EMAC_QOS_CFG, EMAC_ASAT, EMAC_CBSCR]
{0x125C+4i} EMAC_TXPQUANT{i} reset 0xFFFFFFFF (i=1..3) — Express MAC Transmit Pause Quantum {i} Register
  [31:16] QUANT_P{2i+1} — Priority {2i+1} Transmit Pause Quantum
  [15:0] QUANT_P{2i} — Priority {2i} Transmit Pause Quantum
0x1270 EMAC_RXLPI ro — Express MAC Received LPI Transitions
  [15:0] COUNT — Count of Received LPI transitions (cleared on read)
0x1274 EMAC_RXLPITIME ro — Express MAC Received LPI Time
  [23:0] LPITIME — Time in LPI (cleared on read)
0x1278 EMAC_TXLPI ro — Express MAC Transmit LPI Transitions
  [15:0] COUNT — Count of LPI transitions (cleared on read)
0x127C EMAC_TXLPITIME ro — Express MAC Transmit LPI Time
  [23:0] LPITIME — Time in LPI (cleared on read)
0x12E0 EMAC_QOS_CFG — Express MAC System Bus QoS Configuration Register
  [8n+7:8n+4] Q{n}_DESCR (n=0..3) — System Bus QoS Attributes for Queue {n} Descriptor Access
  [8n+3:8n] Q{n}_DATA (n=0..3) — System Bus QoS Attributes for Queue {n} Data Access
{0x1300+8i} GMAC_EMAC_ASA[{i}] (i=0..31) group
  0x00 EMAC_ASAB — Express MAC Additional Specific Address Bottom Register
    [31:0] ADDR — Specific Address
  0x04 EMAC_ASAT — Express MAC Additional Specific Address Top Register
    fields as GMAC_EMAC_SA[0].EMAC_SAT
0x14BC EMAC_CBSCR — Express MAC Credit-Based Shaping Control Register
  [1] QBE — Queue B CBS Enable
    0=Credit-based shaping on the highest priority queue (queue B) is disabled; 1=Credit-based shaping on the highest priority queue (queue B) is enabled
  [0] QAE — Queue A CBS Enable
    0=Credit-based shaping on the second highest priority queue (queue A) is disabled; 1=Credit-based shaping on the second highest priority queue (queue A) is enabled
0x14C0 EMAC_CBSISQA — Express MAC Credit-Based Shaping IdleSlope Register for Queue A
  [31:0] IS — IdleSlope
0x14C4 EMAC_CBSISQB — Express MAC Credit-Based Shaping IdleSlope Register for Queue B
  [31:0] IS — IdleSlope
0x14C8 EMAC_TQUBA — Express MAC 32 MSB Transmit Buffer Descriptor Queue Base Address Register
  [31:0] TQUBA — Transmit Queue Upper Buffer Address
0x14CC EMAC_TXBDCTRL — Express MAC Transmit Buffer Data Control Register
  [5:4] TSMODE — Transmit Descriptor Timestamp Insertion Mode
    0=DISABLE (Timestamp insertion disable.); 1=PTPEVENT (Timestamp inserted for PTP Event Frames only.); 2=PTPALL (Timestamp inserted for All PTP Frames only.); 3=ALL (Timestamp inserted for All Frames.)
0x14D0 EMAC_RXBDCTRL — Express MAC Receive Buffer Data Control Register
  [5:4] TSMODE — Receive Descriptor Timestamp Insertion Mode
    values as EMAC_TXBDCTRL.TSMODE
0x14D4 EMAC_RQUBA — Express MAC 32 MSB Receive Buffer Descriptor Queue Base Address Register
  [31:0] RQUBA — Receive Queue Upper Buffer Address
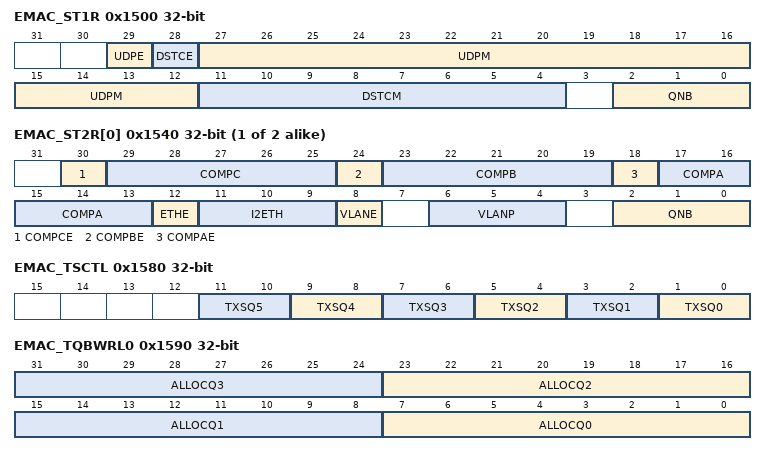
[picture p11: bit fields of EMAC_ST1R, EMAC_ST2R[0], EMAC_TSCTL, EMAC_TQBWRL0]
0x1500 EMAC_ST1R — Express MAC Screening Type 1 Register
  [29] UDPE — UDP Port Match Enable
  [28] DSTCE — Differentiated Services or Traffic Class Match Enable
  [27:12] UDPM — UDP Port Match
  [11:4] DSTCM — Differentiated Services or Traffic Class Match
  [2:0] QNB — Queue Number (0-5)
{0x1540+4i} EMAC_ST2R[{i}] (i=0..1) — Express MAC Screening Type 2 Register (index = 0)
  [30] COMPCE — Compare C Enable
    0=Comparison via the register designated by index COMPC is disabled; 1=Comparison via the register designated by index COMPC is enabled
  [29:25] COMPC — Index of Screening Type 2 Compare Word 0/Word 1 register
  [24] COMPBE — Compare B Enable
    0=Comparison via the register designated by index COMPB is disabled; 1=Comparison via the register designated by index COMPB is enabled
  [23:19] COMPB — Index of Screening Type 2 Compare Word 0/Word 1 register
  [18] COMPAE — Compare A Enable
    0=Comparison via the register designated by index COMPA is disabled; 1=Comparison via the register designated by index COMPA is enabled
  [17:13] COMPA — Index of Screening Type 2 Compare Word 0/Word 1 register
  [12] ETHE — EtherType Enable
    0=EtherType match with bits 15:0 in the register designated by the value of I2ETH is disabled; 1=EtherType match with bits 15:0 in the register designated by the value of I2ETH is enabled
  [11:9] I2ETH — Index of Screening Type 2 EtherType register
  [8] VLANE — VLAN Enable
    0=VLAN match is disabled; 1=VLAN match is enabled
  [6:4] VLANP — VLAN Priority
  [2:0] QNB — Queue Number (0-5)
0x1580 EMAC_TSCTL — Express MACTransmit Schedule Control Register
  [all] fields
    0=FP (Fixed Priority); 1=CBS (CBS Enabled only valid for top two enabled queues and if CBS capability selected.); 2=DWRR (DWRR enabled); 3=ETS (ETS enabled)
  [2n+1:2n] TXSQ{n} (n=0..5) — Transmit Schedule for Qx
0x1590 EMAC_TQBWRL0 — Express MAC Transmit Queue Bandwidth Rate Limit 0 Register
  [8n+7:8n] ALLOCQ{n} (n=0..3) — DWRR Weighting or ETS Bandwidth Allocation for Qx
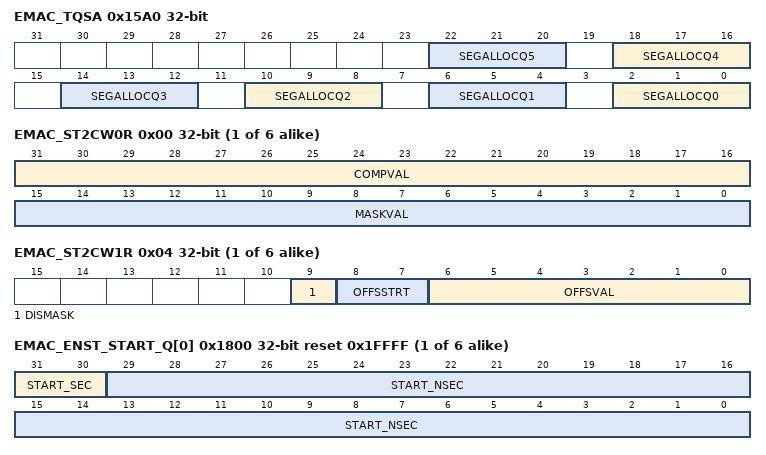
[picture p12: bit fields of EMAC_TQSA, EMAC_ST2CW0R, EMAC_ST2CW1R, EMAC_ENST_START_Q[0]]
0x15A0 EMAC_TQSA — Express MAC Transmit Queue Segment Allocation Register
  [4n+2:4n] SEGALLOCQ{n} (n=0..5) — Segment Allocation for Qx
{0x1700+8i} GMAC_EMAC_ST2CW[{i}] (i=0..5) group
  0x00 EMAC_ST2CW0R — Express MAC Screening Type 2 Compare Word 0 Register
    [31:16] COMPVAL — Compare Value
    [15:0] MASKVAL — Mask Value
  0x04 EMAC_ST2CW1R — Express MAC Screening Type 2 Compare Word 1 Register
    [9] DISMASK — Disable Mask
      0=GMAC_EMAC_ST2CW0R contains a 2-byte compare value with a 2-byte mask value; 1=GMAC_EMAC_ST2CW0R contains a 4-byte compare value
    [8:7] OFFSSTRT — Ethernet Frame Offset Start
      0=FRAMESTART (Offset from the start of the frame); 1=ETHERTYPE (Offset from the byte after the EtherType field); 2=IP (Offset from the byte after the IP header field); 3=TCP_UDP (Offset from the byte after the TCP/UDP header field)
    [6:0] OFFSVAL — Offset Value in Bytes
{0x1800+4i} EMAC_ENST_START_Q[{i}] (i=0..5) reset 0x1FFFF — Express MAC ENST Start Time Queue Register (index = 0)
  [31:30] START_SEC — Seconds for Start Time
  [29:0] START_NSEC — Nanoseconds for Start Time
{0x1820+4i} EMAC_ENST_ON_Q[{i}] (i=0..5) reset 0x1FFFF — Express MAC ENST On Time Queue Register (index = 0)
  [16:0] ON_TIME — Time for which the Queue is to be Open
{0x1840+4i} EMAC_ENST_OFF_Q[{i}] (i=0..5) — Express MAC ENST Off Time Queue Register (index = 0)
  [16:0] OFF_TIME — Time for which the Queue is to be Blocked
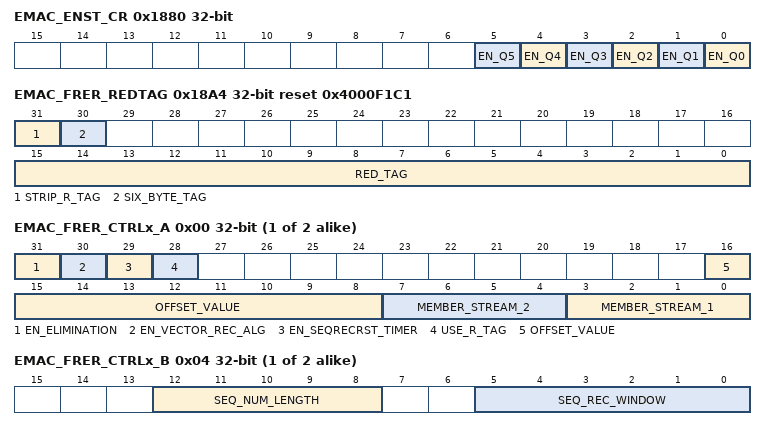
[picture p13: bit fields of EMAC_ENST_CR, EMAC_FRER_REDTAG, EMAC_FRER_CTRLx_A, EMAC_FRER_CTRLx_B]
0x1880 EMAC_ENST_CR — Express MAC ENST Control Register
  [all] fields
    0=Disables the enhanced scheduled traffic for queue x; 1=Enables the enhanced scheduled traffic for queue x. EMAC has only 1 queue and ENST is enabled by writing EN_Q0.
  [n] EN_Q{n} (n=0..5) — Enhanced Scheduled Traffic Enable for Queue {n}
0x18A0 EMAC_FRER_TIMEOUT — Express MAC Frame Elimination Timeout Register
  [15:0] TIMEOUT — Sequence Recovery Timer Restart Period for Credit Based Streams
0x18A4 EMAC_FRER_REDTAG reset 0x4000F1C1 — Express MAC Frame Elimination Redundancy Tag Register
  [31] STRIP_R_TAG — Stripping Redundancy Tag Enable
    0=Disables the stripping function. When the statistics counters need to reflect the actual number of octets received, then the stripping functionality must be disabled.; 1=Enables the stripping function, the receive octet counters reflect post deletion frame size so the frame elimination functionality is transparent to higher level management
  [30] SIX_BYTE_TAG — Six-byte Tag Enable
    0=Defines a four-byte tag as per 802.1CB standard revision 2.4 and earlier; 1=Enables the six-byte tag as per 802.1CB standard revision 2.4 and later
  [15:0] RED_TAG — Redundancy Tag (R-TAG)
{0x18B0+0x10*i} GMAC_EMAC_FRER{i} (i=1..2) group
  0x00 EMAC_FRER_CTRLx_A — Express MAC Frame Elimination Control1 A Register
    [31] EN_ELIMINATION — 802.1CB Elimination of Received Frames Enable
      0=Disables the elimination of received frames; 1=Enables the elimination of received frames
    [30] EN_VECTOR_REC_ALG — 802.1CB Vector Recovery Algorithm Enable
      0=Enables the match recovery algorithm; 1=Enables the vector recovery algorithm
    [29] EN_SEQRECRST_TIMER — 802.1CB Sequence Recovery Reset Timer Enable
      0=Disables the sequence recovery reset timer; 1=Enables the sequence recovery reset timer
    [28] USE_R_TAG — Redundancy Tag Enable
      0=Identifies bottom of sequence number with OFFSET_VALUE; 1=Identifies sequence number with redundancy tag
    [16:8] OFFSET_VALUE — Offset in Bytes from Start Packet Delimiter to MSB for 802.1CB Sequence Number
    [7:4] MEMBER_STREAM_2 — Pointer to Screener Type 2 Register
    [3:0] MEMBER_STREAM_1 — Pointer to Screener Type 2 Register
  0x04 EMAC_FRER_CTRLx_B — Express MAC Frame Elimination Control1 B Register
    [12:8] SEQ_NUM_LENGTH — Number of Significants bits of the 802.1CB Sequence Number
    [5:0] SEQ_REC_WINDOW — Vector Recovery Window
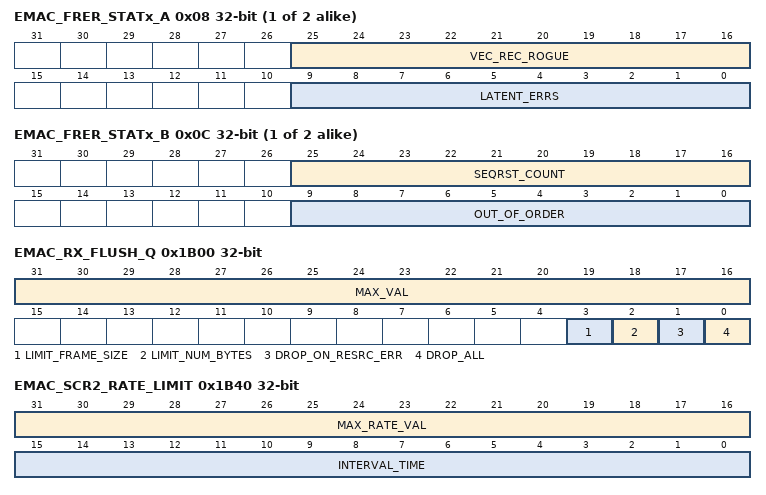
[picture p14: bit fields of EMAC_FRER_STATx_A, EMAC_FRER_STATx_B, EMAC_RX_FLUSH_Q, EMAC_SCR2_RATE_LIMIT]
  0x08 EMAC_FRER_STATx_A — Express MAC Frame Elimination Statistics1 A Register
    [25:16] VEC_REC_ROGUE — Number of Dropped Frames (Clear on read)
    [9:0] LATENT_ERRS — Number of Sequence Numbers Seen Without a Duplicate (Clear on read)
  0x0C EMAC_FRER_STATx_B — Express MAC Frame Elimination Statistics1 B Register
    [25:16] SEQRST_COUNT — Number of Times the Sequence Recovery Reset Timer Decrements to Zero (Clear on read)
    [9:0] OUT_OF_ORDER — Out of Order Sequence Numbers Received (Clear on read)
0x1B00 EMAC_RX_FLUSH_Q — Express MAC Receive Queue Flush Register
  fields as RX_FLUSH_Q[0]
0x1B40 EMAC_SCR2_RATE_LIMIT — Express MAC Screening 2 Rate Limit Register
  fields as SCR2_RATE_LIMIT[0]
0x1B80 EMAC_SCR2_RATE_STATUS ro — Express MAC Screening 2 Rate Status Register
  [all] fields
    0=No excessive rate in screener since the last read of GMAC_EMAC_SCR2_RATE_STATUS; 1=A screener rate limiting mechanism has been triggered since the last read of GMAC_EMAC_SCR2_RATE_STATUS
  [n] EXCESS_RATE_Q{n} (n=0..7) — Excessive Screener Rate Queue {n}

## Notices in the file
Copyright (c) 2026 Microchip Technology Inc.
SPDX-License-Identifier: Apache-2.0
Licensed under the Apache License, Version 2.0 (the "License");
you may not use this file except in compliance with the License.
You may obtain a copy of the License at
http://www.apache.org/licenses/LICENSE-2.0
Unless required by applicable law or agreed to in writing, software
distributed under the License is distributed on an "AS IS" BASIS,
WITHOUT WARRANTIES OR CONDITIONS OF ANY KIND, either express or implied.
See the License for the specific language governing permissions and
limitations under the License.
